AUTOSAR XML (schema 00046)
package /ComponentTypes
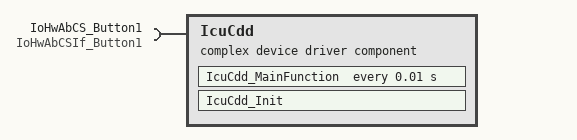
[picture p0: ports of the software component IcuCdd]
  complex device driver sw component type IcuCdd
    require port IoHwAbCS_Button1: client-com-spec=IoHwAbOp_Button1_Read, required-interface=IoHwAbCSIf_Button1
    behavior IcuCdd_InternalBehavior
      init event IcuCdd_InitEvent: start-on-event=IcuCdd_Init
      timing event TMT_IcuCdd_MainFunction: start-on-event=IcuCdd_MainFunction, period=0.01
      runnable IcuCdd_Init
      runnable IcuCdd_MainFunction
        sync call SC_IoHwAbCS_Button1_IoHwAbOp_Button1_Read: operation=IoHwAbCS_Button1.IoHwAbOp_Button1_Read
  swc implementation IcuCdd_Implementation: behavior=IcuCdd_InternalBehavior
